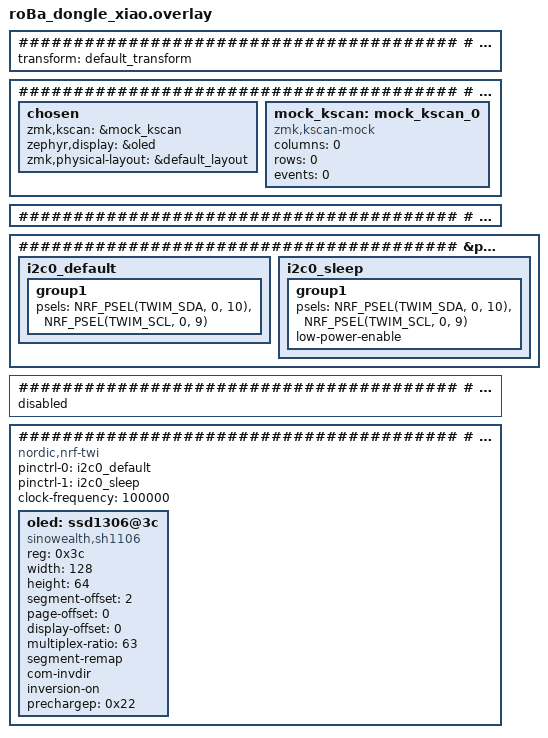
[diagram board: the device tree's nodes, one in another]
#include "roBa.dtsi"
#include "roBa_trackball.dtsi"

########################################
# デフォルトレイアウト設定
########################################
&default_layout {
    transform = <&default_transform>;  /* レイアウト変換を指定 */
};

########################################
# ルートノード設定
########################################
/ {
    chosen {
        zmk,kscan = &mock_kscan;           /* キースキャンにモックを使用 */
        zephyr,display = &oled;            /* OLEDディスプレイを指定 */
        zmk,physical-layout = &default_layout; /* デフォルト物理レイアウトを指定 */
    };

    /* モックキースキャン設定 */
    mock_kscan: mock_kscan_0 {
        compatible = "zmk,kscan-mock";
        columns = <0>;  /* 列数 */
        rows = <0>;     /* 行数 */
        events = <0>;   /* 発火イベント数 */
    };
};

########################################
# トラックボール設定
########################################
&trackball_listener {
    status = "okay";  /* トラックボールを有効化 */
};

########################################
# ピン制御設定 (I2C)
########################################
&pinctrl {
    /* I2C 通常動作用 */
    i2c0_default: i2c0_default {
        group1 {
            psels = <NRF_PSEL(TWIM_SDA, 0, 10)>,
                    <NRF_PSEL(TWIM_SCL, 0, 9)>;
        };
    };

    /* I2C スリープ動作用 */
    i2c0_sleep: i2c0_sleep {
        group1 {
            psels = <NRF_PSEL(TWIM_SDA, 0, 10)>,
                    <NRF_PSEL(TWIM_SCL, 0, 9)>;
            low-power-enable;
        };
    };
};

########################################
# シリアル設定
########################################
&xiao_serial {
    status = "disabled";  /* シリアル無効化 */
};

########################################
# I2C設定
########################################
&xiao_i2c {
    status = "okay";
    compatible = "nordic,nrf-twi";
    pinctrl-0 = <&i2c0_default>;
    pinctrl-1 = <&i2c0_sleep>;
    pinctrl-names = "default", "sleep";
    clock-frequency = <100000>;  /* 100kHz */

    /* OLED ディスプレイ設定 */
    oled: ssd1306@3c {
        compatible = "sinowealth,sh1106";
        reg = <0x3c>;
        width = <128>;
        height = <64>;
        segment-offset = <2>;
        page-offset = <0>;
        display-offset = <0>;
        multiplex-ratio = <63>;
        segment-remap;
        com-invdir;
        inversion-on;
        prechargep = <0x22>;
    };
};
